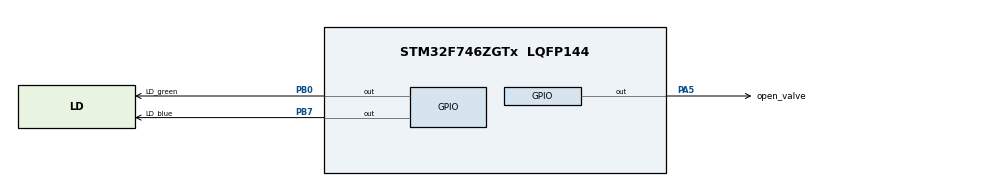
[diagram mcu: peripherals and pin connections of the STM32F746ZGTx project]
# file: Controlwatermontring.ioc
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Mcu.Family=STM32F7
Mcu.Name=STM32F746ZGTx
Mcu.Package=LQFP144
NVIC.PriorityGroup=NVIC_PRIORITYGROUP_4
PA13.Mode=Trace_Asynchronous_SW
PA13.Signal=SYS_JTMS-SWDIO
PA14.Mode=Trace_Asynchronous_SW
PA14.Signal=SYS_JTCK-SWCLK
PA5.GPIO_Label=open_valve
PA5.Signal=GPIO_Output
PB0.GPIO_Label=LD_green
PB0.Signal=GPIO_Output
PB3.Mode=Trace_Asynchronous_SW
PB3.Signal=SYS_JTDO-SWO
PB7.GPIO_Label=LD_blue
PB7.Signal=GPIO_Output
ProjectManager.HeapSize=0x200
ProjectManager.StackSize=0x400
ProjectManager.TargetToolchain=STM32CubeIDE
RCC.HSE_VALUE=25000000
RCC.HSI_VALUE=16000000
RCC.LSE_VALUE=32768
RCC.USBFreq_Value=96000000
RCC.VCOOutputFreq_Value=192000000
board=custom

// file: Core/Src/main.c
/* USER CODE BEGIN Header */
/**
  ******************************************************************************
  * @file           : main.c
  * @brief          : Main program body
  ******************************************************************************
  * @attention
  *
  * Copyright (c) 2023 STMicroelectronics.
  * All rights reserved.
  *
  * This software is licensed under terms that can be found in the LICENSE file
  * in the root directory of this software component.
  * If no LICENSE file comes with this software, it is provided AS-IS.
  *
  ******************************************************************************
  */
/* USER CODE END Header */
#include "main.h"
#include"stdio.h"

void SystemClock_Config(void);
static void MX_GPIO_Init(void);
void Test_Sensor();

/* USER CODE BEGIN 0 */

uint16_t Loop = 0;
uint16_t Data = 0;

/* USER CODE END 0 */

int main(void)
{

	/* USER CODE BEGIN 1 */

//	// Enable access to the embedded flash memory
//	    HAL_FLASH_Unlock();
//
//	    // Get the device electronic signature
//
//	    const uint32_t *uid = (const uint32_t *)0x1FF0F420;
//
//
//
//	    // Lock the embedded flash memory
//	    HAL_FLASH_Lock();

  /* USER CODE END 1 */

  /* MCU Configuration--------------------------------------------------------*/

  /* Reset of all peripherals, Initializes the Flash interface and the Systick. */
  HAL_Init();

  /* Configure the system clock */
  SystemClock_Config();

  /* Initialize all configured peripherals */
  MX_GPIO_Init();

  /* Infinite loop */
  /* USER CODE BEGIN WHILE */
  // Initialize peripherals, GPIOs, etc.

  while (1)
  {

	      Sensor* pSensor1 = sensor_create();
	      sensor_set_filter_freq(pSensor1, 100);
	      sensor_set_update_freq(pSensor1, 10);

	      printf("fillter_freq: %d\n", sensor_get_filter_freq(pSensor1));
	      printf("update_freq: %d\n", sensor_get_update_freq(pSensor1));

	      sensor_destroy(pSensor1);

//	  printf("I'm in the main loop!\r\n");
//	 	  HAL_GPIO_TogglePin(GPIOB,LD_blue_Pin);
//	 	  HAL_Delay(500);
//	 	  printf("Loop Counter = %i\r\n", Loop);
//	 	  Loop++;
//	 	  if(Loop > 100){
//	 		  Loop = 0;
//	 	  }
//	 	  HAL_Delay(50);
//	 	  if(Loop < 25){
//	 		  Data += 5;
//	 	  }
//	 	  else{
//	 		  Data -=1000;
//	 	  }

    /* USER CODE END WHILE */

  }
}

void SystemClock_Config(void)
{
  RCC_OscInitTypeDef RCC_OscInitStruct = {0};
  RCC_ClkInitTypeDef RCC_ClkInitStruct = {0};

  /** Configure the main internal regulator output voltage
  */
  __HAL_RCC_PWR_CLK_ENABLE();
  __HAL_PWR_VOLTAGESCALING_CONFIG(PWR_REGULATOR_VOLTAGE_SCALE3);

  /** Initializes the RCC Oscillators according to the specified parameters
  * in the RCC_OscInitTypeDef structure.
  */
  RCC_OscInitStruct.OscillatorType = RCC_OSCILLATORTYPE_HSI;
  RCC_OscInitStruct.HSIState = RCC_HSI_ON;
  RCC_OscInitStruct.HSICalibrationValue = RCC_HSICALIBRATION_DEFAULT;
  RCC_OscInitStruct.PLL.PLLState = RCC_PLL_NONE;
  if (HAL_RCC_OscConfig(&RCC_OscInitStruct) != HAL_OK)
  {
    Error_Handler();
  }

  /** Initializes the CPU, AHB and APB buses clocks
  */
  RCC_ClkInitStruct.ClockType = RCC_CLOCKTYPE_HCLK|RCC_CLOCKTYPE_SYSCLK
                              |RCC_CLOCKTYPE_PCLK1|RCC_CLOCKTYPE_PCLK2;
  RCC_ClkInitStruct.SYSCLKSource = RCC_SYSCLKSOURCE_HSI;
  RCC_ClkInitStruct.AHBCLKDivider = RCC_SYSCLK_DIV1;
  RCC_ClkInitStruct.APB1CLKDivider = RCC_HCLK_DIV1;
  RCC_ClkInitStruct.APB2CLKDivider = RCC_HCLK_DIV1;

  if (HAL_RCC_ClockConfig(&RCC_ClkInitStruct, FLASH_LATENCY_0) != HAL_OK)
  {
    Error_Handler();
  }
}

static void MX_GPIO_Init(void)
{
  GPIO_InitTypeDef GPIO_InitStruct = {0};

  /* GPIO Ports Clock Enable */
  __HAL_RCC_GPIOA_CLK_ENABLE();
  __HAL_RCC_GPIOB_CLK_ENABLE();

  /*Configure GPIO pin Output Level */
  HAL_GPIO_WritePin(open_valve_GPIO_Port, open_valve_Pin, GPIO_PIN_RESET);

  /*Configure GPIO pin Output Level */
  HAL_GPIO_WritePin(GPIOB, LD_green_Pin|LD_blue_Pin, GPIO_PIN_RESET);

  /*Configure GPIO pin : open_valve_Pin */
  GPIO_InitStruct.Pin = open_valve_Pin;
  GPIO_InitStruct.Mode = GPIO_MODE_OUTPUT_PP;
  GPIO_InitStruct.Pull = GPIO_NOPULL;
  GPIO_InitStruct.Speed = GPIO_SPEED_FREQ_LOW;
  HAL_GPIO_Init(open_valve_GPIO_Port, &GPIO_InitStruct);

  /*Configure GPIO pins : LD_green_Pin LD_blue_Pin */
  GPIO_InitStruct.Pin = LD_green_Pin|LD_blue_Pin;
  GPIO_InitStruct.Mode = GPIO_MODE_OUTPUT_PP;
  GPIO_InitStruct.Pull = GPIO_NOPULL;
  GPIO_InitStruct.Speed = GPIO_SPEED_FREQ_LOW;
  HAL_GPIO_Init(GPIOB, &GPIO_InitStruct);

}

/* USER CODE BEGIN 4 */

int _write(int file, char *ptr, int len)
{
  (void)file;
  int DataIdx;

  for (DataIdx = 0; DataIdx < len; DataIdx++)
  {

    ITM_SendChar(*ptr++);
  }
  return len;
}

/* USER CODE END 4 */

void Error_Handler(void)
{
  __disable_irq();
  while (1)
  {
  }
}
